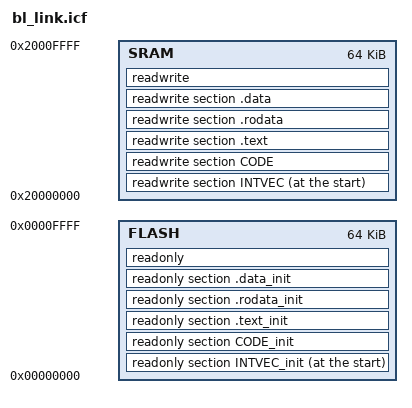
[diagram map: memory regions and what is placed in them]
//*****************************************************************************
//
// bl_link.icf - Linker script for EW-ARM.
//
// Copyright (c) 2007-2009 Luminary Micro, Inc.  All rights reserved.
// Software License Agreement
// 
// Luminary Micro, Inc. (LMI) is supplying this software for use solely and
// exclusively on LMI's microcontroller products.
// 
// The software is owned by LMI and/or its suppliers, and is protected under
// applicable copyright laws.  All rights are reserved.  You may not combine
// this software with "viral" open-source software in order to form a larger
// program.  Any use in violation of the foregoing restrictions may subject
// the user to criminal sanctions under applicable laws, as well as to civil
// liability for the breach of the terms and conditions of this license.
// 
// THIS SOFTWARE IS PROVIDED "AS IS".  NO WARRANTIES, WHETHER EXPRESS, IMPLIED
// OR STATUTORY, INCLUDING, BUT NOT LIMITED TO, IMPLIED WARRANTIES OF
// MERCHANTABILITY AND FITNESS FOR A PARTICULAR PURPOSE APPLY TO THIS SOFTWARE.
// LMI SHALL NOT, IN ANY CIRCUMSTANCES, BE LIABLE FOR SPECIAL, INCIDENTAL, OR
// CONSEQUENTIAL DAMAGES, FOR ANY REASON WHATSOEVER.
// 
// This is part of revision 4423 of the Stellaris Firmware Development Package.
//
//*****************************************************************************

//
// Define a memory region that covers the entire 4 GB addressible space of the
// processor.
//
define memory mem with size = 4G;

//
// Define a region for the on-chip flash.
//
define region FLASH = mem:[from 0x00000000 to 0x0000ffff];

//
// Define a region for the on-chip SRAM.
//
define region SRAM = mem:[from 0x20000000 to 0x2000ffff];

//
// Indicate that the sections containing the boot loader code should be
// initialized by copying.
//
initialize by copy { section INTVEC };
initialize by copy { section CODE };
initialize by copy { section .text };
initialize by copy { section .rodata };
initialize by copy { section .data };

keep { section INTVEC };
keep { section INTVEC_init };

//
// Indicate that the noinit values should be left alone.  This includes the
// stack, which if initialized will destroy the return address from the
// initialization code, causing the processor to branch to zero and fault.
//
do not initialize { section .noinit };

//
// Place the interrupt vectors at the start of flash/SRAM.
//
place at start of FLASH { readonly section INTVEC_init };
place at start of SRAM { readwrite section INTVEC };

//
// Place the remainder of the read-only items into flash/SRAM.
//
place in FLASH { readonly section CODE_init };
place in SRAM { readwrite section CODE };
place in FLASH { readonly section .text_init };
place in SRAM { readwrite section .text };
place in FLASH { readonly section .rodata_init };
place in SRAM { readwrite section .rodata };
place in FLASH { readonly section .data_init };
place in SRAM { readwrite section .data };
place in FLASH { readonly };

//
// Place all read/write items into SRAM.
//
place in SRAM { readwrite };
